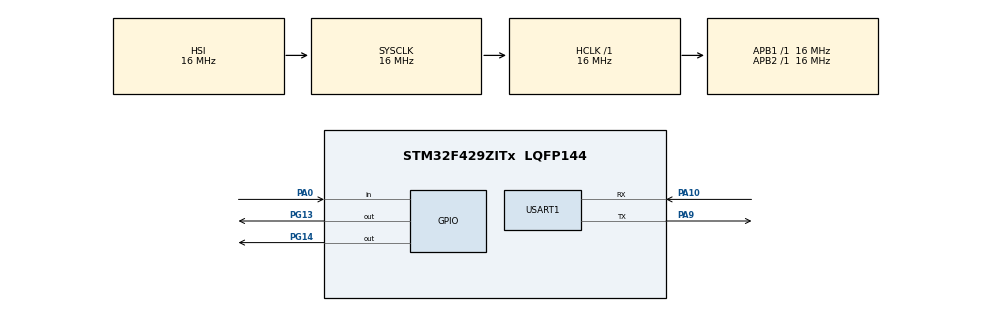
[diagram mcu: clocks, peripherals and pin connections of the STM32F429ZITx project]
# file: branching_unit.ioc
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Mcu.Family=STM32F4
Mcu.Name=STM32F429ZITx
Mcu.Package=LQFP144
NVIC.PriorityGroup=NVIC_PRIORITYGROUP_4
PA0/WKUP.Signal=GPIO_Input
PA10.Mode=Asynchronous
PA10.Signal=USART1_RX
PA9.Mode=Asynchronous
PA9.Signal=USART1_TX
PG13.Signal=GPIO_Output
PG14.Signal=GPIO_Output
ProjectManager.HeapSize=0x200
ProjectManager.StackSize=0x400
ProjectManager.TargetToolchain=STM32CubeIDE
RCC.AHBFreq_Value=16000000
RCC.APB1Freq_Value=16000000
RCC.APB2Freq_Value=16000000
RCC.CortexFreq_Value=16000000
RCC.HSE_VALUE=25000000
RCC.HSI_VALUE=16000000
RCC.LSE_VALUE=32768
RCC.SYSCLKFreq_VALUE=16000000
RCC.VCOOutputFreq_Value=192000000
USART1.VirtualMode=VM_ASYNC
VP_RTC_VS_RTC_Activate.Mode=RTC_Enabled
board=custom

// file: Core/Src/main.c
/* USER CODE BEGIN Header */
/**
 ******************************************************************************
 * @file           : main.c
 * @brief          : Main program body
 ******************************************************************************/
#include "main.h"

/* USER CODE BEGIN Includes */
#include <stdio.h>

RTC_HandleTypeDef hrtc;

UART_HandleTypeDef huart1;
volatile uint32_t* USER_APP_ADDRESS = 0x08010000;

void SystemClock_Config(void);
static void MX_GPIO_Init(void);
static void MX_USART1_UART_Init(void);
static void MX_RTC_Init(void);

void branching_unit(void);
void Jump_To_Bootloader(void);
void Jump_To_User_App(void);

void branching_unit()
{

	if (HAL_RTCEx_BKUPRead(&hrtc, RTC_BKP_DR0) == 0x0000)
	{
		if(*USER_APP_ADDRESS != 0xFFFFFFFF){
			Jump_To_User_App();
		}
		// First time boot
		Jump_To_Bootloader();
	}
	else
	{
		Jump_To_Bootloader();
	}

}

void Jump_To_Bootloader() {
	// Turn on Green LED
	HAL_GPIO_WritePin(GPIOG, GPIO_PIN_13, GPIO_PIN_SET);
	printf("Starting Bootloader \r\n");
	HAL_Delay(2000);
	void (*app_reset_handler)(void);
	uint32_t msp_value = *(volatile uint32_t*) 0x08004000;
	__set_MSP(msp_value);
	uint32_t resethandler_address = *(volatile uint32_t*) (0x08004000 + 4);
	app_reset_handler = (void*) resethandler_address;
	app_reset_handler();
}

void Jump_To_User_App() {
	// Turn on RED LED
	HAL_GPIO_WritePin(GPIOG, GPIO_PIN_14, GPIO_PIN_SET);
	printf("Starting Application \r\n");
	HAL_Delay(2000);
	void (*app_reset_handler)(void);
	uint32_t msp_value = *(volatile uint32_t*) 0x08010000;
	__set_MSP(msp_value);
	uint32_t resethandler_address = *(volatile uint32_t*) (0x08010000 + 4);
	app_reset_handler = (void*) resethandler_address;
	app_reset_handler();
}
int main(void)
{

	/* Reset of all peripherals, Initializes the Flash interface and the Systick. */
	HAL_Init();
	SystemClock_Config();
	/* Initialize all configured peripherals */
	MX_GPIO_Init();
	MX_USART1_UART_Init();
	MX_RTC_Init();
	branching_unit();
	while (1)
	{
	}
}

void SystemClock_Config(void)
{
	RCC_OscInitTypeDef RCC_OscInitStruct = {0};
	RCC_ClkInitTypeDef RCC_ClkInitStruct = {0};

	/** Configure the main internal regulator output voltage
	 */
	__HAL_RCC_PWR_CLK_ENABLE();
	__HAL_PWR_VOLTAGESCALING_CONFIG(PWR_REGULATOR_VOLTAGE_SCALE3);

	/** Initializes the RCC Oscillators according to the specified parameters
	 * in the RCC_OscInitTypeDef structure.
	 */
	RCC_OscInitStruct.OscillatorType = RCC_OSCILLATORTYPE_HSI|RCC_OSCILLATORTYPE_LSI;
	RCC_OscInitStruct.HSIState = RCC_HSI_ON;
	RCC_OscInitStruct.HSICalibrationValue = RCC_HSICALIBRATION_DEFAULT;
	RCC_OscInitStruct.LSIState = RCC_LSI_ON;
	RCC_OscInitStruct.PLL.PLLState = RCC_PLL_NONE;
	if (HAL_RCC_OscConfig(&RCC_OscInitStruct) != HAL_OK)
	{
		Error_Handler();
	}

	/** Initializes the CPU, AHB and APB buses clocks
	 */
	RCC_ClkInitStruct.ClockType = RCC_CLOCKTYPE_HCLK|RCC_CLOCKTYPE_SYSCLK
			|RCC_CLOCKTYPE_PCLK1|RCC_CLOCKTYPE_PCLK2;
	RCC_ClkInitStruct.SYSCLKSource = RCC_SYSCLKSOURCE_HSI;
	RCC_ClkInitStruct.AHBCLKDivider = RCC_SYSCLK_DIV1;
	RCC_ClkInitStruct.APB1CLKDivider = RCC_HCLK_DIV1;
	RCC_ClkInitStruct.APB2CLKDivider = RCC_HCLK_DIV1;

	if (HAL_RCC_ClockConfig(&RCC_ClkInitStruct, FLASH_LATENCY_0) != HAL_OK)
	{
		Error_Handler();
	}
}

static void MX_RTC_Init(void)
{

	/** Initialize RTC Only
	 */
	hrtc.Instance = RTC;
	hrtc.Init.HourFormat = RTC_HOURFORMAT_24;
	hrtc.Init.AsynchPrediv = 127;
	hrtc.Init.SynchPrediv = 255;
	hrtc.Init.OutPut = RTC_OUTPUT_DISABLE;
	hrtc.Init.OutPutPolarity = RTC_OUTPUT_POLARITY_HIGH;
	hrtc.Init.OutPutType = RTC_OUTPUT_TYPE_OPENDRAIN;
	if (HAL_RTC_Init(&hrtc) != HAL_OK)
	{
		Error_Handler();
	}

}

static void MX_USART1_UART_Init(void)
{

	/* USER CODE END USART1_Init 1 */
	huart1.Instance = USART1;
	huart1.Init.BaudRate = 115200;
	huart1.Init.WordLength = UART_WORDLENGTH_8B;
	huart1.Init.StopBits = UART_STOPBITS_1;
	huart1.Init.Parity = UART_PARITY_NONE;
	huart1.Init.Mode = UART_MODE_TX_RX;
	huart1.Init.HwFlowCtl = UART_HWCONTROL_NONE;
	huart1.Init.OverSampling = UART_OVERSAMPLING_16;
	if (HAL_UART_Init(&huart1) != HAL_OK)
	{
		Error_Handler();
	}

}

static void MX_GPIO_Init(void)
{
	GPIO_InitTypeDef GPIO_InitStruct = {0};

	/* GPIO Ports Clock Enable */
	__HAL_RCC_GPIOA_CLK_ENABLE();
	__HAL_RCC_GPIOG_CLK_ENABLE();

	/*Configure GPIO pin Output Level */
	HAL_GPIO_WritePin(GPIOG, GPIO_PIN_13|GPIO_PIN_14, GPIO_PIN_RESET);

	/*Configure GPIO pin : PA0 */
	GPIO_InitStruct.Pin = GPIO_PIN_0;
	GPIO_InitStruct.Mode = GPIO_MODE_INPUT;
	GPIO_InitStruct.Pull = GPIO_NOPULL;
	HAL_GPIO_Init(GPIOA, &GPIO_InitStruct);

	/*Configure GPIO pins : PG13 PG14 */
	GPIO_InitStruct.Pin = GPIO_PIN_13|GPIO_PIN_14;
	GPIO_InitStruct.Mode = GPIO_MODE_OUTPUT_PP;
	GPIO_InitStruct.Pull = GPIO_NOPULL;
	GPIO_InitStruct.Speed = GPIO_SPEED_FREQ_LOW;
	HAL_GPIO_Init(GPIOG, &GPIO_InitStruct);

}

/* USER CODE BEGIN 4 */
/**
 * @brief Print the characters to UART (printf).
 * @retval int
 */
#ifdef __GNUC__
/* With GCC, small printf (option LD Linker->Libraries->Small printf
     set to 'Yes') calls __io_putchar() */
int __io_putchar(int ch)
#else
int fputc(int ch, FILE *f)
#endif /* __GNUC__ */
{
	/* Place your implementation of fputc here */
	/* e.g. write a character to the UART1 and Loop until the end of transmission */
	HAL_UART_Transmit(&huart1, (uint8_t *)&ch, 1, HAL_MAX_DELAY);
	return ch;
}
/* USER CODE END 4 */

void Error_Handler(void)
{
	__disable_irq();
	while (1)
	{
	}
}
